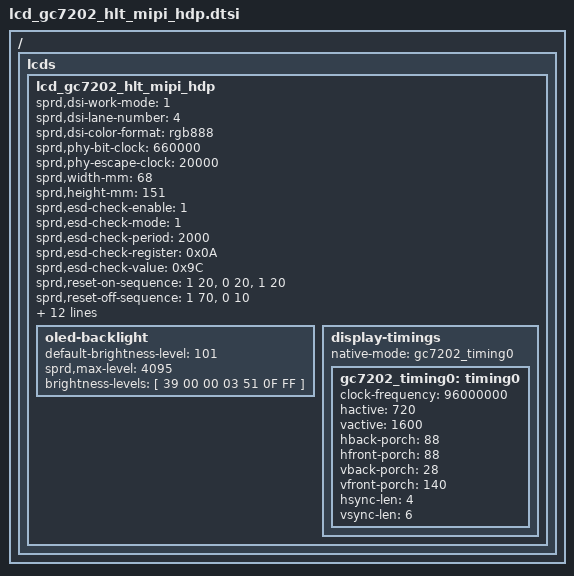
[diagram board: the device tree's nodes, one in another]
/ {
	fragment {
		target-path = "/";
		__overlay__ {
				lcds {
					lcd_gc7202_hlt_mipi_hdp: lcd_gc7202_hlt_mipi_hdp {

						sprd,dsi-work-mode = <1>; /* video burst mode*/
						sprd,dsi-lane-number = <4>;
						sprd,dsi-color-format = "rgb888";

						sprd,phy-bit-clock = <660000>;	/* kbps */
						sprd,phy-escape-clock = <20000>;/* kHz */

						sprd,width-mm = <68>;
						sprd,height-mm = <151>;

						sprd,esd-check-enable = <1>;
						sprd,esd-check-mode = <1>;
						sprd,esd-check-period = <2000>;
						sprd,esd-check-register = <0x0A>;
						sprd,esd-check-value = <0x9C>;

						sprd,reset-on-sequence = <1 20>, <0 20>, <1 20>;
						sprd,reset-off-sequence = <1 70>, <0 10>;

						sprd,use-dcs-write;

						sprd,initial-command = [
							29 00 00 04 FF 55 AA 66
							29 00 00 02 FF 20
							29 00 00 02 FB 00
							29 00 00 02 FF 21
							29 00 00 02 FB 00
							29 00 00 02 FF 22
							29 00 00 02 FB 00
							29 00 00 02 FF 23
							29 00 00 02 FB 00
							29 00 00 02 FF 24
							29 00 00 02 FB 00
							29 00 00 02 FF 26
							29 00 00 02 FB 00
							29 00 00 02 FF 27
							29 00 00 02 FB 00
							29 00 00 02 FF A3
							29 00 00 02 FB 00
							29 00 00 02 FF B3
							29 00 00 02 FB 00
							29 00 00 02 FF C3
							29 00 00 02 FB 00
							29 00 00 02 FF 27
							29 00 00 11 01 A2 20 00 10 32 54 76 98 BA 00 00 00 00 00 00 00
							29 00 00 11 02 00 01 02 03 04 05 06 07 08 09 0A 0B 00 00 00 00
							29 00 00 11 03 40 10 08 00 00 00 00 00 00 00 88 04 00 00 00 00
							29 00 00 11 04 03 25 80 55 5D 55 AD 05 00 00 1C 00 00 00 00 00
							29 00 00 11 06 40 00 00 00 40 55 00 03 12 13 02 01 19 00 00 00
							29 00 00 11 07 00 00 00 00 00 00 40 00 00 00 00 00 00 00 00 00
							29 00 00 11 08 45 86 02 00 00 00 00 00 D0 00 80 00 00 00 00 00
							29 00 00 11 09 00 00 00 00 00 00 00 00 00 00 00 00 00 00 00 00
							29 00 00 11 0A 00 00 00 00 00 00 00 00 00 00 00 00 00 00 00 00
							29 00 00 11 0B 00 00 00 00 00 00 00 00 00 00 00 00 00 00 00 00
							29 00 00 11 0C 00 00 00 00 00 00 00 00 00 00 00 03 FF 00 26 04
							29 00 00 11 0D 00 64 CB 00 33 03 00 00 00 00 00 00 00 00 00 00
							29 00 00 09 10 FF 00 FF 00 FF 00 FF 00
							29 00 00 11 43 CF 06 55 10 CF 02 57 10 CF 08 54 10 CF 06 55 10
							29 00 00 11 44 CF 08 54 10 D1 00 58 10 CE 44 36 10 00 00 00 00
							29 00 00 11 45 00 00 00 00 00 00 00 00 1E 40 55 55 07 40 55 55
							29 00 00 11 46 57 40 55 55 97 46 55 55 27 00 00 00 00 00 00 00
							29 00 00 11 47 27 40 17 07 00 00 00 00 27 40 17 07 00 00 00 00
							29 00 00 11 48 27 40 17 07 28 08 09 00 D9 06 78 06 2B 06 55 10
							29 00 00 11 49 2B 06 55 10 2B 06 55 10 2B 02 57 10 2B 08 54 10
							29 00 00 11 4A 2B 06 55 10 2B 08 54 10 2D 00 58 10 2A 44 36 10
							29 00 00 11 4B 00 00 00 00 00 00 00 00 00 00 00 00 00 00 00 00
							29 00 00 11 4C 00 00 00 00 04 40 00 00 41 46 00 00 27 00 00 00
							29 00 00 11 4D 00 00 00 00 00 00 70 06 00 00 00 00 00 00 70 06
							29 00 00 11 4E 00 00 00 00 00 00 70 06 28 08 09 01 11 00 58 01
							29 00 00 11 4F 2B 06 55 10 2B 06 55 10 2B 06 55 10 2B 02 57 10
							29 00 00 11 50 2B 08 54 10 2B 06 55 10 2B 08 54 10 2D 00 58 10
							29 00 00 11 51 2A 44 36 10 00 00 00 00 00 00 00 00 00 00 00 00
							29 00 00 11 52 00 00 00 00 00 00 00 00 04 00 01 00 41 06 01 00
							29 00 00 11 53 27 00 00 00 00 00 00 00 00 00 70 06 00 00 00 00
							29 00 00 11 54 00 00 70 06 00 00 00 00 00 00 70 06 28 08 09 02
							29 00 00 11 55 11 00 58 01 2B 06 55 10 2B 06 55 10 2B 06 55 10
							29 00 00 11 56 2B 02 57 10 2B 08 54 10 2B 06 55 10 2B 08 54 10
							29 00 00 11 57 2D 00 58 10 2A 44 36 10 00 00 00 00 00 00 00 00
							29 00 00 11 58 00 00 00 00 00 00 00 00 00 00 00 00 04 00 04 00
							29 00 00 11 59 41 06 04 00 27 00 00 00 00 00 00 00 00 00 70 06
							29 00 00 11 5A 00 00 00 00 00 00 70 06 00 00 00 00 00 00 70 06
							29 00 00 11 5B 28 08 09 03 11 00 58 01 2B 06 55 10 2B 06 55 10
							29 00 00 11 5C 2B 06 55 10 2B 02 57 10 2B 08 54 10 2B 06 55 10
							29 00 00 11 5D 2B 08 54 10 2D 00 58 10 2A 44 36 10 00 00 00 00
							29 00 00 11 5E 00 00 00 00 00 00 00 00 00 00 00 00 00 00 00 00
							29 00 00 11 5F 04 00 10 00 41 06 10 00 27 00 00 00 00 00 00 00
							29 00 00 11 60 00 00 70 06 00 00 00 00 00 00 70 06 00 00 00 00
							29 00 00 11 61 00 00 70 06 28 08 09 04 11 00 58 01 2B 06 55 10
							29 00 00 11 62 2B 06 55 10 2B 06 55 10 2B 02 57 10 2B 08 54 10
							29 00 00 11 63 2B 06 55 10 2B 08 54 10 2D 00 58 10 2A 44 36 10
							29 00 00 11 64 00 00 00 00 00 00 00 00 00 00 00 00 00 00 00 00
							29 00 00 11 65 00 00 00 00 04 00 40 00 41 06 40 00 27 00 00 00
							29 00 00 11 66 00 00 00 00 00 00 70 06 00 00 00 00 00 00 70 06
							29 00 00 11 67 00 00 00 00 00 00 70 06 28 08 09 05 11 00 58 01
							29 00 00 11 68 2B 06 55 10 2B 06 55 10 2B 06 55 10 2B 02 57 10
							29 00 00 11 69 2B 08 54 10 2B 06 55 10 2B 08 54 10 2D 00 58 10
							29 00 00 11 6A 2A 44 36 10 00 00 00 00 00 00 00 00 00 00 00 00
							29 00 00 11 6B 00 00 00 00 00 00 00 00 04 00 00 01 41 06 00 01
							29 00 00 11 6C 27 00 00 00 00 00 00 00 00 00 70 06 00 00 00 00
							29 00 00 11 6D 00 00 70 06 00 00 00 00 00 00 70 06 28 08 09 06
							29 00 00 11 6E 11 00 58 01 2B 06 55 10 2B 06 55 10 2B 06 55 10
							29 00 00 11 6F 2B 02 57 10 2B 08 54 10 2B 06 55 10 2B 08 54 10
							29 00 00 11 70 2D 00 58 10 2A 44 36 10 00 00 00 00 00 00 00 00
							29 00 00 11 71 00 00 00 00 00 00 00 00 00 00 00 00 04 00 00 04
							29 00 00 11 72 41 06 00 04 27 00 00 00 00 00 00 00 00 00 70 06
							29 00 00 11 73 00 00 00 00 00 00 70 06 00 00 00 00 00 00 70 06
							29 00 00 11 74 28 08 09 07 11 00 58 01 2B 06 55 10 2B 06 55 10
							29 00 00 11 75 2B 06 55 10 2B 02 57 10 2B 08 54 10 2B 06 55 10
							29 00 00 11 76 2B 08 54 10 2D 00 58 10 2A 44 36 10 00 00 00 00
							29 00 00 11 77 00 00 00 00 00 00 00 00 00 00 00 00 00 00 00 00
							29 00 00 11 78 04 00 00 10 41 06 00 10 27 00 00 00 00 00 00 00
							29 00 00 11 79 00 00 70 06 00 00 00 00 00 00 70 06 00 00 00 00
							29 00 00 11 7A 00 00 70 06 28 08 09 08 11 00 58 01 2B 06 55 10
							29 00 00 11 7B 2B 06 55 10 2B 06 55 10 2B 02 57 10 2B 08 54 10
							29 00 00 11 7C 2B 06 55 10 2B 08 54 10 2D 00 58 10 2A 44 36 10
							29 00 00 11 7D 09 00 00 40 41 06 00 40 07 C0 FF FF 21 80 AA AA
							29 00 00 11 7E 04 00 00 00 00 00 00 00 00 00 00 00 00 00 00 00
							29 00 00 11 7F 53 86 00 00 00 00 27 00 53 86 00 00 00 00 27 00
							29 00 00 11 80 53 86 00 00 00 00 27 00 28 08 09 09 11 00 58 11
							29 00 00 11 81 00 00 00 00 00 00 00 00 00 00 00 00 00 00 00 00
							29 00 00 11 82 00 00 00 00 00 00 00 00 00 00 00 00 00 00 00 00
							29 00 00 11 83 00 00 00 00 00 00 00 00 00 00 00 00 00 00 00 00
							29 00 00 11 84 00 00 00 00 00 00 00 00 00 00 00 00 00 00 00 00
							29 00 00 11 85 00 00 00 00 00 00 00 00 00 00 00 00 00 00 00 00
							29 00 00 11 86 00 00 00 00 00 00 00 00 00 00 00 00 00 00 00 0A
							29 00 00 11 87 00 00 00 00 00 00 00 00 00 00 00 00 00 00 00 00
							29 00 00 11 88 00 00 00 00 00 00 00 00 00 00 00 00 00 00 00 00
							29 00 00 11 89 00 00 00 00 00 00 00 00 00 00 00 00 00 00 00 00
							29 00 00 11 8A 00 00 00 00 00 00 00 00 00 00 00 00 00 00 00 00
							29 00 00 11 8B 00 00 00 00 00 00 00 00 00 00 00 00 00 00 00 00
							29 00 00 11 8C 00 00 00 00 00 00 00 00 00 00 00 00 00 00 00 00
							29 00 00 09 8D 00 00 00 0B 00 00 F0 00
							29 00 00 02 FF 22
							29 00 00 02 E4 01
							29 00 00 02 01 06
							29 00 00 02 02 40
							29 00 00 02 25 08
							29 00 00 02 26 00
							29 00 00 02 2E 6F
							29 00 00 02 2F 00
							29 00 00 02 36 09
							29 00 00 02 37 00
							29 00 00 02 3F 6F
							29 00 00 02 40 00
							29 00 00 02 0E 33
							29 00 00 02 DC 77
							29 00 00 02 08 40
							29 00 00 02 FF 21
							29 00 00 02 01 25
							29 00 00 02 02 05
							29 00 00 02 03 1A
							29 00 00 02 04 25
							29 00 00 02 05 25
							29 00 00 02 06 01
							29 00 00 02 07 0F
							29 00 00 02 08 0D
							29 00 00 02 09 0B
							29 00 00 02 0A 09
							29 00 00 02 0B 23
							29 00 00 02 0C 23
							29 00 00 02 0D 25
							29 00 00 02 0E 25
							29 00 00 02 0F 25
							29 00 00 02 10 25
							29 00 00 02 11 25
							29 00 00 02 12 25
							29 00 00 02 13 25
							29 00 00 02 14 25
							29 00 00 02 15 25
							29 00 00 02 16 25
							29 00 00 02 17 25
							29 00 00 02 18 04
							29 00 00 02 19 1A
							29 00 00 02 1A 25
							29 00 00 02 1B 25
							29 00 00 02 1C 00
							29 00 00 02 1D 0E
							29 00 00 02 1E 0C
							29 00 00 02 1F 0A
							29 00 00 02 20 08
							29 00 00 02 21 23
							29 00 00 02 22 23
							29 00 00 02 23 25
							29 00 00 02 24 25
							29 00 00 02 25 25
							29 00 00 02 26 25
							29 00 00 02 27 25
							29 00 00 02 28 25
							29 00 00 02 29 25
							29 00 00 02 2A 25
							29 00 00 02 2B 25
							29 00 00 02 2E 00
							29 00 00 02 88 A7
							29 00 00 02 89 28
							29 00 00 02 8A 33
							29 00 00 02 94 A7
							29 00 00 02 95 28
							29 00 00 02 96 33
							29 00 00 02 45 73
							29 00 00 02 46 53
							29 00 00 02 47 02
							29 00 00 02 48 01
							29 00 00 02 4C 53
							29 00 00 02 4D 01
							29 00 00 02 4E 02
							29 00 00 02 5E 41
							29 00 00 02 5F 21
							29 00 00 02 60 22
							29 00 00 02 64 41
							29 00 00 02 65 22
							29 00 00 02 66 21
							29 00 00 02 7B 04
							29 00 00 02 7C 04
							29 00 00 02 7D 04
							29 00 00 02 7E 03
							29 00 00 02 7F 21
							29 00 00 02 80 01
							29 00 00 02 81 1A
							29 00 00 02 82 50
							29 00 00 02 83 04
							29 00 00 02 87 00
							29 00 00 02 8B 21
							29 00 00 02 8C 1A
							29 00 00 02 8D 01
							29 00 00 02 8E 50
							29 00 00 02 8F 04
							29 00 00 02 93 00
							29 00 00 02 76 40
							29 00 00 02 77 40
							29 00 00 02 7A 44
							29 00 00 02 7B 44
							29 00 00 02 AF 40
							29 00 00 02 B0 40
							29 00 00 02 C2 80
							29 00 00 02 C6 14
							29 00 00 02 D1 13
							29 00 00 02 49 32
							29 00 00 02 4A 32
							29 00 00 02 4F 32
							29 00 00 02 50 32
							29 00 00 02 61 32
							29 00 00 02 62 32
							29 00 00 02 67 32
							29 00 00 02 68 32
							29 00 00 02 6D 32
							29 00 00 02 6E 32
							29 00 00 02 84 32
							29 00 00 02 85 32
							29 00 00 02 90 32
							29 00 00 02 91 32
							29 00 00 02 30 00
							29 00 00 02 31 00
							29 00 00 02 DC 27
							29 00 00 02 E0 80
							29 00 00 02 E1 27
							29 00 00 02 E2 80
							29 00 00 02 FF B3
							29 00 00 02 4A 00
							29 00 00 02 7D 28
							29 00 00 02 5B 00
							29 00 00 02 48 23
							29 00 00 02 7C 88
							29 00 00 02 79 20
							29 00 00 02 3E 03
							29 00 00 02 82 10  //0906
							29 00 00 02 3F 7f
							29 00 00 02 5E 10
							29 00 00 02 58 84
							29 00 00 02 53 1A
							29 00 00 02 01 BB  //0906
							29 00 00 02 10 0B  //0906
							29 00 00 02 FF C3
							29 00 00 02 06 14  //0906
							29 00 00 02 FF 20
							29 00 00 02 29 01
							29 00 00 02 2D 1F
							29 00 00 02 02 27
							29 00 00 02 03 27
							29 00 00 02 04 45
							29 00 00 02 05 45
							29 00 00 02 0A 1B
							29 00 00 02 0B 1B
							29 00 00 02 0C 4B
							29 00 00 02 0D 4B
							29 00 00 02 77 74
							29 00 00 02 78 74
							29 00 00 02 1C 28
							29 00 00 02 1D 28
							29 00 00 02 A5 00
							29 00 00 02 A6 FF
							29 00 00 02 A9 00
							29 00 00 02 AA FF
							29 00 00 02 AD 00
							29 00 00 02 AE FF
							29 00 00 02 B1 00
							29 00 00 02 B2 FF
							29 00 00 02 C3 00
							29 00 00 02 C4 5F
							29 00 00 02 C5 00
							29 00 00 02 C6 5F
							29 00 00 02 B3 00
							29 00 00 02 B4 20
							29 00 00 02 B5 00
							29 00 00 02 B6 DC
							29 00 00 02 C7 00
							29 00 00 02 C8 93
							29 00 00 02 C9 00
							29 00 00 02 CA 93
							29 00 00 02 B7 00
							29 00 00 02 B8 20
							29 00 00 02 B9 01
							29 00 00 02 BA 90
							29 00 00 02 CB 00
							29 00 00 02 CC 90
							29 00 00 02 BB 00
							29 00 00 02 BC 16
							29 00 00 02 BD 00
							29 00 00 02 BE 12
							29 00 00 02 D5 0E
							29 00 00 02 7E 01
							29 00 00 02 7F 00
							29 00 00 02 80 01
							29 00 00 02 81 00
							29 00 00 02 82 00
							29 00 00 02 83 04
							29 00 00 02 84 04
							29 00 00 02 85 01  //0906
							29 00 00 02 86 8B  //0906
							29 00 00 02 87 01  //0906
							29 00 00 02 88 8B  //0906
							29 00 00 02 8A 03
							29 00 00 02 8B 03
							29 00 00 02 18 44  //0906
							29 00 00 02 17 51
							29 00 00 02 12 A2
							29 00 00 02 15 4C  //0906
							29 00 00 02 A3 44
							29 00 00 02 A7 44
							29 00 00 02 4B FF
							29 00 00 02 4C FF
							29 00 00 02 4D FF
							29 00 00 02 D3 03
							29 00 00 02 24 99
							29 00 00 02 2D 1F
							29 00 00 02 25 06
							//29 00 00 02 51 0B

							29 00 00 02 FF 23
							29 00 00 11 01 00 00 00 1F 00 35 00 4C 00 6D 00 85 00 9A 00 AC
							29 00 00 11 02 00 C0 00 F6 01 1C 01 52 01 77 01 AA 01 D5 01 D6
							29 00 00 11 03 02 04 02 3E 02 66 02 9C 02 C1 02 F1 03 01 03 14
							29 00 00 0D 04 03 2A 03 42 03 5F 03 87 03 CA 03 E8
							29 00 00 11 05 00 00 00 1F 00 35 00 4C 00 6D 00 85 00 9A 00 AC
							29 00 00 11 06 00 C0 00 F6 01 1C 01 52 01 77 01 AA 01 D5 01 D6
							29 00 00 11 07 02 04 02 3E 02 66 02 9C 02 C1 02 F1 03 01 03 14
							29 00 00 0D 08 03 2A 03 42 03 5F 03 87 03 CA 03 E8
							29 00 00 11 09 00 00 00 1F 00 35 00 4C 00 6D 00 85 00 9A 00 AC
							29 00 00 11 0A 00 C0 00 F6 01 1C 01 52 01 77 01 AA 01 D5 01 D6
							29 00 00 11 0B 02 04 02 3E 02 66 02 9C 02 C1 02 F1 03 01 03 14
							29 00 00 0D 0C 03 2A 03 42 03 5F 03 87 03 CA 03 E8
							29 00 00 11 0D 00 00 00 1F 00 35 00 4C 00 6D 00 85 00 9A 00 AC
							29 00 00 11 0E 00 C0 00 F6 01 1C 01 52 01 77 01 AA 01 D5 01 D6
							29 00 00 11 0F 02 04 02 3E 02 66 02 9C 02 C1 02 F1 03 01 03 14
							29 00 00 0D 10 03 2A 03 42 03 5F 03 87 03 CA 03 E8
							29 00 00 11 11 00 00 00 1F 00 35 00 4C 00 6D 00 85 00 9A 00 AC
							29 00 00 11 12 00 C0 00 F6 01 1C 01 52 01 77 01 AA 01 D5 01 D6
							29 00 00 11 13 02 04 02 3E 02 66 02 9C 02 C1 02 F1 03 01 03 14
							29 00 00 0D 14 03 2A 03 42 03 5F 03 87 03 CA 03 E8
							29 00 00 11 15 00 00 00 1F 00 35 00 4C 00 6D 00 85 00 9A 00 AC
							29 00 00 11 16 00 C0 00 F6 01 1C 01 52 01 77 01 AA 01 D5 01 D6
							29 00 00 11 17 02 04 02 3E 02 66 02 9C 02 C1 02 F1 03 01 03 14
							29 00 00 0D 18 03 2A 03 42 03 5F 03 87 03 CA 03 E8
							29 00 00 02 2D 61
							29 00 00 02 2E 00
							29 00 00 02 32 00
							29 00 00 02 33 30
							29 00 00 02 B9 31
							29 00 00 02 B8 b7
							29 00 00 02 35 16
							29 00 00 02 36 0C
							29 00 00 02 30 00
							29 00 00 11 1F 0a 00 20 00 44 00 70 00 96 00 e6 00 0a 00 20 00
							29 00 00 09 20 44 00 70 00 96 00 FF 00
							29 00 00 11 21 a7 00 b2 00 c0 00 cd 00 dd 00 f3 00 d4 00 e4 00
							29 00 00 09 22 ec 00 F1 00 F4 00 FF 00
							29 00 00 11 23 00 00 00 00 00 00 00 00 00 00 00 00 00 00 00 00
							29 00 00 09 24 00 00 00 00 00 00 00 00

							29 00 00 02 FF 26
							29 00 00 05 1D 0C 00 00 00 
							29 00 00 02 1C 23  //0906
							29 00 00 02 FF 10
							29 00 00 03 51 00 00
							29 00 00 02 53 2C
							29 00 00 02 55 00
							29 00 00 02 36 08
							29 00 00 02 69 00
							29 00 00 02 35 00
							//29 00 00 02 FF 10   //0906
							05 78 00 01 11
							29 00 00 02 FF A3
							29 00 00 02 FA 01
							29 00 00 02 35 00
							29 00 00 02 45 10  //0906
							29 00 00 02 05 05
							//29 00 00 02 31 44
							29 00 00 02 FF 10
							05 78 00 01 29
						];

						sprd,sleep-in-command = [
							39 00 00 04 FF 55 AA 66
							15 00 00 02 FF 20
							15 00 00 02 4A 01
							15 00 00 02 48 10
							15 00 00 02 49 00
							15 00 00 02 FF 21
							15 00 00 02 FB 00
							15 00 00 02 D1 00
							15 00 00 02 FF 10
							05 64 00 01 28
							05 78 00 01 10
							39 00 00 04 FF 55 AA 66
							15 00 00 02 FF 26
							15 00 00 02 FB 00
							39 00 00 05 1D A2 AA AA 0A
							15 00 00 02 FF 10
							15 00 00 02 FB 00
							15 00 00 02 4F 01
						];//gesture off

						sprd,sleep-gesture-command = [
							39 00 00 04 FF 55 AA 66
							15 00 00 02 FF 20
							15 00 00 02 4A 01
							15 00 00 02 48 10
							15 00 00 02 49 00
							15 00 00 02 FF 21
							15 00 00 02 FB 00
							15 00 00 02 D1 00
							15 00 00 02 FF 10
							05 64 00 01 28
							05 78 00 01 10
						];//gesture on

						sprd,sleep-out-command = [
							05 78 00 01 11
							05 23 00 01 29
						];

						sprd,cabc-ui-mode = [
							15 00 00 02 55 01
						];

						sprd,cabc-mov-mode = [
							15 00 00 02 55 03
						];

						sprd,cabc-off-mode = [
							15 00 00 02 55 02
						];

						oled-backlight {
							default-brightness-level = <101>;
							sprd,max-level = <4095>;
							brightness-levels = [
								39 00 00 03 51 0F FF
							];
						};
						display-timings {
							native-mode = <&gc7202_timing0>;

							gc7202_timing0: timing0 {
								clock-frequency = <96000000>;
								hactive = <720>;
								vactive = <1600>;
								hback-porch = <88>;
								hfront-porch = <88>;
								vback-porch = <28>;
								vfront-porch = <140>;
								hsync-len = <4>;
								vsync-len = <6>;
							};
						};
					};
				};
		};
	};
};

